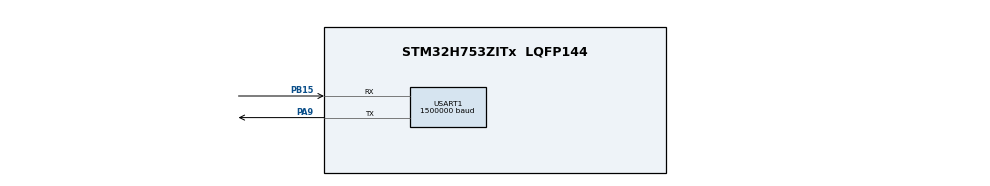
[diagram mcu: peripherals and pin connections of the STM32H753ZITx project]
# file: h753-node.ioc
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CORTEX_M7.AccessPermission_Spec=MPU_REGION_FULL_ACCESS
CORTEX_M7.BaseAddress_Spec=0x30000000
CORTEX_M7.CPU_DCache=Enabled
CORTEX_M7.CPU_ICache=Enabled
CORTEX_M7.DisableExec_Spec=MPU_INSTRUCTION_ACCESS_ENABLE
CORTEX_M7.Enable_S-Cortex_Memory_Protection_Unit_Region1_Settings_S=__NULL
CORTEX_M7.IsShareable_Spec=MPU_ACCESS_NOT_SHAREABLE
CORTEX_M7.MPU_Control=MPU_PRIVILEGED_DEFAULT
CORTEX_M7.Size_Spec=MPU_REGION_SIZE_32KB
CORTEX_M7.SubRegionDisable_Spec=0x00
CORTEX_M7.default_mode_Activation=1
CRYP.Algorithm=CRYP_AES_CBC
CRYP.KeySize=CRYP_KEYSIZE_256B
Dma.Request0=USART1_RX
Dma.USART1_RX.0.Direction=DMA_PERIPH_TO_MEMORY
Dma.USART1_RX.0.EventEnable=DISABLE
Dma.USART1_RX.0.FIFOMode=DMA_FIFOMODE_DISABLE
Dma.USART1_RX.0.Instance=DMA1_Stream0
Dma.USART1_RX.0.MemDataAlignment=DMA_MDATAALIGN_BYTE
Dma.USART1_RX.0.MemInc=DMA_MINC_ENABLE
Dma.USART1_RX.0.Mode=DMA_CIRCULAR
Dma.USART1_RX.0.PeriphDataAlignment=DMA_PDATAALIGN_BYTE
Dma.USART1_RX.0.PeriphInc=DMA_PINC_DISABLE
Dma.USART1_RX.0.Polarity=HAL_DMAMUX_REQ_GEN_RISING
Dma.USART1_RX.0.Priority=DMA_PRIORITY_HIGH
Dma.USART1_RX.0.RequestNumber=1
Dma.USART1_RX.0.SignalID=NONE
Dma.USART1_RX.0.SyncEnable=DISABLE
Dma.USART1_RX.0.SyncPolarity=HAL_DMAMUX_SYNC_NO_EVENT
Dma.USART1_RX.0.SyncRequestNumber=1
Dma.USART1_RX.0.SyncSignalID=NONE
FREERTOS.Queues01=qParsedData,8,uint16_t,0,Dynamic,NULL,NULL;qEncryptedFrames,8,uint16_t,0,Dynamic,NULL,NULL;qeyUpdates,2,uint16_t,0,Dynamic,NULL,NULL
FREERTOS.Tasks01=vTaskIngestion,40,512,StartIngestTask,Default,NULL,Dynamic,NULL,NULL;vTaskCrypto,24,512,StartCryptoTask,Default,NULL,Dynamic,NULL,NULL;vTaskTransmit,24,256,StartTransmitTask,Default,NULL,Dynamic,NULL,NULL
Mcu.Family=STM32H7
Mcu.Name=STM32H753ZITx
Mcu.Package=LQFP144
NUCLEO-H753ZI.BUTTON=1
NUCLEO-H753ZI.LD1=true
NUCLEO-H753ZI.LD2=true
NUCLEO-H753ZI.LD3=true
NUCLEO-H753ZI.VCP=true
NVIC.DMA1_Stream0_IRQn=true\:5\:0\:false\:false\:true\:true\:false\:true\:true
NVIC.EXTI15_10_IRQn=true\:5\:0\:false\:false\:true\:true\:false\:true\:true
NVIC.PriorityGroup=NVIC_PRIORITYGROUP_4
NVIC.TIM1_UP_IRQn=true\:15\:0\:false\:false\:true\:false\:false\:true\:true
NVIC.TimeBase=TIM1_UP_IRQn
NVIC.TimeBaseIP=TIM1
NVIC.USART1_IRQn=true\:5\:0\:false\:false\:true\:true\:true\:true\:true
PA9.Mode=Asynchronous
PA9.Signal=USART1_TX
PB15.Mode=Asynchronous
PB15.Signal=USART1_RX
PC14-OSC32_IN\ (OSC32_IN).Signal=RCC_OSC32_IN
PC15-OSC32_OUT\ (OSC32_OUT).Signal=RCC_OSC32_OUT
PD8.Signal=USART3_TX
PD9.Signal=USART3_RX
PH0-OSC_IN\ (PH0).Signal=RCC_OSC_IN
PH1-OSC_OUT\ (PH1).Signal=RCC_OSC_OUT
ProjectManager.HeapSize=0x200
ProjectManager.StackSize=0x400
ProjectManager.TargetToolchain=CMake
RCC.ADCFreq_Value=129000000
RCC.APB1Freq_Value=64000000
RCC.APB2Freq_Value=64000000
RCC.APB3Freq_Value=64000000
RCC.APB4Freq_Value=64000000
RCC.CortexFreq_Value=64000000
RCC.DIVM1=1
RCC.DIVN1=24
RCC.DIVQ1=4
RCC.HCLKFreq_Value=64000000
RCC.HSE_VALUE=8000000
RCC.PLLFRACN=0
RCC.PWR_Regulator_Voltage_Scale=PWR_REGULATOR_VOLTAGE_SCALE2
RCC.SYSCLKFreq_VALUE=64000000
RCC.USBFreq_Value=384000000
USART1.BaudRate=1500000
USART1.VirtualMode-Asynchronous=VM_ASYNC
VP_CRYP_VS_CRYP.Mode=CRYP_Activate
VP_FREERTOS_VS_CMSIS_V2.Mode=CMSIS_V2
VP_MEMORYMAP_VS_MEMORYMAP.Mode=CurAppReg
VP_NUCLEO-H753ZI_VS_BSP_COMMON.Mode=COMMON
VP_SYS_VS_tim1.Mode=TIM1
board=NUCLEO-H753ZI

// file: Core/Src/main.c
/* USER CODE BEGIN Header */
/**
  ******************************************************************************
  * @file           : main.c
  * @brief          : Main program body
  ******************************************************************************
  * @attention
  *
  * Copyright (c) 2026 STMicroelectronics.
  * All rights reserved.
  *
  * This software is licensed under terms that can be found in the LICENSE file
  * in the root directory of this software component.
  * If no LICENSE file comes with this software, it is provided AS-IS.
  *
  ******************************************************************************
  */
/* USER CODE END Header */
#include "main.h"
#include "app_main.h"
#include "FreeRTOS.h"
#include "task.h"
#include "cmsis_os2.h"

COM_InitTypeDef BspCOMInit;

CRYP_HandleTypeDef hcryp;
__ALIGN_BEGIN static const uint32_t pKeyCRYP[8] __ALIGN_END = {
                            0x00000000,0x00000000,0x00000000,0x00000000,0x00000000,0x00000000,0x00000000,0x00000000};
__ALIGN_BEGIN static const uint32_t pInitVectCRYP[4] __ALIGN_END = {
                            0x00000000,0x00000000,0x00000000,0x00000000};

UART_HandleTypeDef huart1;
DMA_HandleTypeDef hdma_usart1_rx;

/* Definitions for vTaskIngestion */
osThreadId_t vTaskIngestionHandle;
const osThreadAttr_t vTaskIngestion_attributes = {
  .name = "vTaskIngestion",
  .stack_size = 512 * 4,
  .priority = (osPriority_t) osPriorityHigh,
};
/* Definitions for vTaskCrypto */
osThreadId_t vTaskCryptoHandle;
const osThreadAttr_t vTaskCrypto_attributes = {
  .name = "vTaskCrypto",
  .stack_size = 512 * 4,
  .priority = (osPriority_t) osPriorityNormal,
};
/* Definitions for vTaskTransmit */
osThreadId_t vTaskTransmitHandle;
const osThreadAttr_t vTaskTransmit_attributes = {
  .name = "vTaskTransmit",
  .stack_size = 256 * 4,
  .priority = (osPriority_t) osPriorityNormal,
};
/* Definitions for qParsedData */
osMessageQueueId_t qParsedDataHandle;
const osMessageQueueAttr_t qParsedData_attributes = {
  .name = "qParsedData"
};
/* Definitions for qEncryptedFrames */
osMessageQueueId_t qEncryptedFramesHandle;
const osMessageQueueAttr_t qEncryptedFrames_attributes = {
  .name = "qEncryptedFrames"
};
/* Definitions for qeyUpdates */
osMessageQueueId_t qeyUpdatesHandle;
const osMessageQueueAttr_t qeyUpdates_attributes = {
  .name = "qeyUpdates"
};

void SystemClock_Config(void);
static void MPU_Config(void);
static void MX_GPIO_Init(void);
static void MX_DMA_Init(void);
static void MX_USART1_UART_Init(void);
static void MX_CRYP_Init(void);
void StartIngestTask(void *argument);
void StartCryptoTask(void *argument);
void StartTransmitTask(void *argument);

int main(void)
{

  /* MPU Configuration--------------------------------------------------------*/
  MPU_Config();

  /* Enable the CPU Cache */

  /* Enable I-Cache---------------------------------------------------------*/
  SCB_EnableICache();

  /* Enable D-Cache---------------------------------------------------------*/
  SCB_EnableDCache();

  /* MCU Configuration--------------------------------------------------------*/

  /* Reset of all peripherals, Initializes the Flash interface and the Systick. */
  HAL_Init();

  /* Configure the system clock */
  SystemClock_Config();

  /* Initialize all configured peripherals */
  MX_GPIO_Init();
  MX_DMA_Init();
  MX_USART1_UART_Init();
  MX_CRYP_Init();
  /* USER CODE BEGIN 2 */
  App_Init();
  /* USER CODE END 2 */

  /* Init scheduler */
  osKernelInitialize();

  /* Create the queue(s) */
  /* creation of qParsedData */
  qParsedDataHandle = osMessageQueueNew (8, sizeof(uint16_t), &qParsedData_attributes);

  /* creation of qEncryptedFrames */
  qEncryptedFramesHandle = osMessageQueueNew (8, sizeof(uint16_t), &qEncryptedFrames_attributes);

  /* creation of qeyUpdates */
  qeyUpdatesHandle = osMessageQueueNew (2, sizeof(uint16_t), &qeyUpdates_attributes);

  /* Create the thread(s) */
  /* creation of vTaskIngestion */
  vTaskIngestionHandle = osThreadNew(StartIngestTask, NULL, &vTaskIngestion_attributes);

  /* creation of vTaskCrypto */
  vTaskCryptoHandle = osThreadNew(StartCryptoTask, NULL, &vTaskCrypto_attributes);

  /* creation of vTaskTransmit */
  vTaskTransmitHandle = osThreadNew(StartTransmitTask, NULL, &vTaskTransmit_attributes);

  /* Initialize leds */
  BSP_LED_Init(LED_GREEN);
  BSP_LED_Init(LED_YELLOW);
  BSP_LED_Init(LED_RED);

  /* Initialize USER push-button, will be used to trigger an interrupt each time it's pressed.*/
  BSP_PB_Init(BUTTON_USER, BUTTON_MODE_EXTI);

  /* Initialize COM1 port (115200, 8 bits (7-bit data + 1 stop bit), no parity */
  BspCOMInit.BaudRate   = 115200;
  BspCOMInit.WordLength = COM_WORDLENGTH_8B;
  BspCOMInit.StopBits   = COM_STOPBITS_1;
  BspCOMInit.Parity     = COM_PARITY_NONE;
  BspCOMInit.HwFlowCtl  = COM_HWCONTROL_NONE;
  if (BSP_COM_Init(COM1, &BspCOMInit) != BSP_ERROR_NONE)
  {
    Error_Handler();
  }

  /* Start scheduler */
  osKernelStart();

  /* We should never get here as control is now taken by the scheduler */

  /* Infinite loop */
  while (1)
  {

  }
}

void SystemClock_Config(void)
{
  RCC_OscInitTypeDef RCC_OscInitStruct = {0};
  RCC_ClkInitTypeDef RCC_ClkInitStruct = {0};

  /** Supply configuration update enable
  */
  HAL_PWREx_ConfigSupply(PWR_LDO_SUPPLY);

  /** Configure the main internal regulator output voltage
  */
  __HAL_PWR_VOLTAGESCALING_CONFIG(PWR_REGULATOR_VOLTAGE_SCALE2);

  while(!__HAL_PWR_GET_FLAG(PWR_FLAG_VOSRDY)) {}

  /** Initializes the RCC Oscillators according to the specified parameters
  * in the RCC_OscInitTypeDef structure.
  */
  RCC_OscInitStruct.OscillatorType = RCC_OSCILLATORTYPE_HSI;
  RCC_OscInitStruct.HSIState = RCC_HSI_DIV1;
  RCC_OscInitStruct.HSICalibrationValue = RCC_HSICALIBRATION_DEFAULT;
  RCC_OscInitStruct.PLL.PLLState = RCC_PLL_NONE;
  if (HAL_RCC_OscConfig(&RCC_OscInitStruct) != HAL_OK)
  {
    Error_Handler();
  }

  /** Initializes the CPU, AHB and APB buses clocks
  */
  RCC_ClkInitStruct.ClockType = RCC_CLOCKTYPE_HCLK|RCC_CLOCKTYPE_SYSCLK
                              |RCC_CLOCKTYPE_PCLK1|RCC_CLOCKTYPE_PCLK2
                              |RCC_CLOCKTYPE_D3PCLK1|RCC_CLOCKTYPE_D1PCLK1;
  RCC_ClkInitStruct.SYSCLKSource = RCC_SYSCLKSOURCE_HSI;
  RCC_ClkInitStruct.SYSCLKDivider = RCC_SYSCLK_DIV1;
  RCC_ClkInitStruct.AHBCLKDivider = RCC_HCLK_DIV1;
  RCC_ClkInitStruct.APB3CLKDivider = RCC_APB3_DIV1;
  RCC_ClkInitStruct.APB1CLKDivider = RCC_APB1_DIV1;
  RCC_ClkInitStruct.APB2CLKDivider = RCC_APB2_DIV1;
  RCC_ClkInitStruct.APB4CLKDivider = RCC_APB4_DIV1;

  if (HAL_RCC_ClockConfig(&RCC_ClkInitStruct, FLASH_LATENCY_1) != HAL_OK)
  {
    Error_Handler();
  }
}

static void MX_CRYP_Init(void)
{

  hcryp.Instance = CRYP;
  hcryp.Init.DataType = CRYP_DATATYPE_32B;
  hcryp.Init.KeySize = CRYP_KEYSIZE_256B;
  hcryp.Init.pKey = (uint32_t *)pKeyCRYP;
  hcryp.Init.pInitVect = (uint32_t *)pInitVectCRYP;
  hcryp.Init.Algorithm = CRYP_AES_CBC;
  if (HAL_CRYP_Init(&hcryp) != HAL_OK)
  {
    Error_Handler();
  }

}

static void MX_USART1_UART_Init(void)
{

  huart1.Instance = USART1;
  huart1.Init.BaudRate = 1500000;
  huart1.Init.WordLength = UART_WORDLENGTH_8B;
  huart1.Init.StopBits = UART_STOPBITS_1;
  huart1.Init.Parity = UART_PARITY_NONE;
  huart1.Init.Mode = UART_MODE_TX_RX;
  huart1.Init.HwFlowCtl = UART_HWCONTROL_NONE;
  huart1.Init.OverSampling = UART_OVERSAMPLING_16;
  huart1.Init.OneBitSampling = UART_ONE_BIT_SAMPLE_DISABLE;
  huart1.Init.ClockPrescaler = UART_PRESCALER_DIV1;
  huart1.AdvancedInit.AdvFeatureInit = UART_ADVFEATURE_NO_INIT;
  if (HAL_UART_Init(&huart1) != HAL_OK)
  {
    Error_Handler();
  }
  if (HAL_UARTEx_SetTxFifoThreshold(&huart1, UART_TXFIFO_THRESHOLD_1_8) != HAL_OK)
  {
    Error_Handler();
  }
  if (HAL_UARTEx_SetRxFifoThreshold(&huart1, UART_RXFIFO_THRESHOLD_1_8) != HAL_OK)
  {
    Error_Handler();
  }
  if (HAL_UARTEx_DisableFifoMode(&huart1) != HAL_OK)
  {
    Error_Handler();
  }

}

static void MX_DMA_Init(void)
{

  /* DMA controller clock enable */
  __HAL_RCC_DMA1_CLK_ENABLE();

  /* DMA interrupt init */
  /* DMA1_Stream0_IRQn interrupt configuration */
  HAL_NVIC_SetPriority(DMA1_Stream0_IRQn, 5, 0);
  HAL_NVIC_EnableIRQ(DMA1_Stream0_IRQn);

}

static void MX_GPIO_Init(void)
{

  /* GPIO Ports Clock Enable */
  __HAL_RCC_GPIOC_CLK_ENABLE();
  __HAL_RCC_GPIOH_CLK_ENABLE();
  __HAL_RCC_GPIOB_CLK_ENABLE();
  __HAL_RCC_GPIOA_CLK_ENABLE();

}

void StartIngestTask(void *argument)
{
  /* USER CODE BEGIN 5 */
  /* Infinite loop */
  for(;;)
  {
    HAL_GPIO_TogglePin(GPIOB, GPIO_PIN_0); // Toggle LED 1 (Adjust pin for your board)
    vTaskDelay(pdMS_TO_TICKS(100));        // 100ms delay (using native FreeRTOS)
  }
  /* USER CODE END 5 */
}

void StartCryptoTask(void *argument)
{
  for(;;)
  {
    osDelay(1);
  }
}

void StartTransmitTask(void *argument)
{
  /* USER CODE BEGIN StartTransmitTask */
  volatile uint32_t heartbeat_counter = 0;
  /* Infinite loop */
  for(;;)
  {
    HAL_GPIO_TogglePin(GPIOB, GPIO_PIN_14); // Toggle LED 2
    heartbeat_counter++;
    vTaskDelay(pdMS_TO_TICKS(1000));        // 1000ms delay
  }
  /* USER CODE END StartTransmitTask */
}

 /* MPU Configuration */

void MPU_Config(void)
{
  MPU_Region_InitTypeDef MPU_InitStruct = {0};

  /* Disables the MPU */
  HAL_MPU_Disable();

  /** Initializes and configures the Region and the memory to be protected
  */
  MPU_InitStruct.Enable = MPU_REGION_ENABLE;
  MPU_InitStruct.Number = MPU_REGION_NUMBER0;
  MPU_InitStruct.BaseAddress = 0x30000000;
  MPU_InitStruct.Size = MPU_REGION_SIZE_32KB;
  MPU_InitStruct.SubRegionDisable = 0x00;
  MPU_InitStruct.TypeExtField = MPU_TEX_LEVEL0;
  MPU_InitStruct.AccessPermission = MPU_REGION_FULL_ACCESS;
  MPU_InitStruct.DisableExec = MPU_INSTRUCTION_ACCESS_ENABLE;
  MPU_InitStruct.IsShareable = MPU_ACCESS_NOT_SHAREABLE;
  MPU_InitStruct.IsCacheable = MPU_ACCESS_NOT_CACHEABLE;
  MPU_InitStruct.IsBufferable = MPU_ACCESS_NOT_BUFFERABLE;

  HAL_MPU_ConfigRegion(&MPU_InitStruct);
  /* Enables the MPU */
  HAL_MPU_Enable(MPU_PRIVILEGED_DEFAULT);

}

void HAL_TIM_PeriodElapsedCallback(TIM_HandleTypeDef *htim)
{
  if (htim->Instance == TIM1)
  {
    HAL_IncTick();
  }
}

void Error_Handler(void)
{
  __disable_irq();
  while (1)
  {
  }
}
